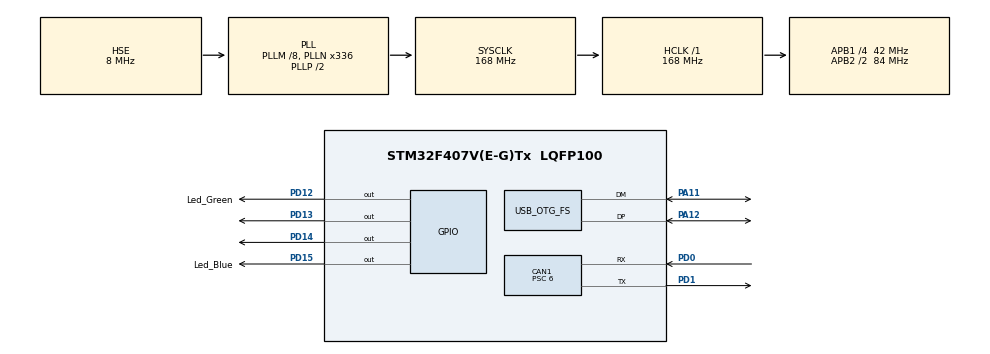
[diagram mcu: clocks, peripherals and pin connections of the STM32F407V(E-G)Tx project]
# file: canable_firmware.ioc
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CAN1.BS1=CAN_BS1_11TQ
CAN1.BS2=CAN_BS2_2TQ
CAN1.CalculateBaudRate=500000
CAN1.CalculateTimeBit=2000
CAN1.CalculateTimeQuantum=142.85714285714286
CAN1.Prescaler=6
Mcu.Family=STM32F4
Mcu.Name=STM32F407V(E-G)Tx
Mcu.Package=LQFP100
NVIC.CAN1_RX0_IRQn=true\:0\:2\:false\:false\:true\:true\:true\:true
NVIC.CAN1_RX1_IRQn=true\:0\:0\:false\:false\:true\:true\:true\:true
NVIC.CAN1_SCE_IRQn=true\:0\:0\:false\:false\:true\:true\:true\:true
NVIC.CAN1_TX_IRQn=true\:0\:0\:false\:false\:true\:true\:true\:true
NVIC.OTG_FS_IRQn=true\:0\:0\:false\:false\:true\:true\:true\:true
NVIC.PriorityGroup=NVIC_PRIORITYGROUP_0
PA11.Mode=Device_Only
PA11.Signal=USB_OTG_FS_DM
PA12.Mode=Device_Only
PA12.Signal=USB_OTG_FS_DP
PC14-OSC32_IN.Mode=LSE-External-Oscillator
PC14-OSC32_IN.Signal=RCC_OSC32_IN
PC15-OSC32_OUT.Mode=LSE-External-Oscillator
PC15-OSC32_OUT.Signal=RCC_OSC32_OUT
PD0.Mode=CAN_Activate
PD0.Signal=CAN1_RX
PD1.Mode=CAN_Activate
PD1.Signal=CAN1_TX
PD12.GPIO_Label=Led_Green
PD12.Signal=GPIO_Output
PD13.Signal=GPIO_Output
PD14.Signal=GPIO_Output
PD15.GPIO_Label=Led_Blue
PD15.Signal=GPIO_Output
PH0-OSC_IN.Mode=HSE-External-Oscillator
PH0-OSC_IN.Signal=RCC_OSC_IN
PH1-OSC_OUT.Mode=HSE-External-Oscillator
PH1-OSC_OUT.Signal=RCC_OSC_OUT
ProjectManager.HeapSize=0x200
ProjectManager.StackSize=0x400
ProjectManager.TargetToolchain=STM32CubeIDE
RCC.48MHZClocksFreq_Value=48000000
RCC.AHBFreq_Value=168000000
RCC.APB1CLKDivider=RCC_HCLK_DIV4
RCC.APB1Freq_Value=42000000
RCC.APB1TimFreq_Value=84000000
RCC.APB2CLKDivider=RCC_HCLK_DIV2
RCC.APB2Freq_Value=84000000
RCC.APB2TimFreq_Value=168000000
RCC.CortexFreq_Value=168000000
RCC.HCLKFreq_Value=168000000
RCC.HSE_VALUE=8000000
RCC.HSI_VALUE=16000000
RCC.PLLM=8
RCC.PLLN=336
RCC.PLLQ=7
RCC.SYSCLKFreq_VALUE=168000000
RCC.SYSCLKSource=RCC_SYSCLKSOURCE_PLLCLK
RCC.VCOOutputFreq_Value=336000000
USB_DEVICE.CLASS_NAME_FS=CUSTOM_HID
USB_DEVICE.USBD_CUSTOMHID_OUTREPORT_BUF_SIZE-CUSTOM_HID_FS=17
USB_DEVICE.USBD_CUSTOM_HID_REPORT_DESC_SIZE-CUSTOM_HID_FS=33
USB_DEVICE.VirtualMode-CUSTOM_HID_FS=CustomHid
USB_DEVICE.VirtualModeFS=Custom_Hid_FS
USB_OTG_FS.VirtualMode=Device_Only
VP_USB_DEVICE_VS_USB_DEVICE_CUSTOM_HID_FS.Mode=CUSTOM_HID_FS
board=STM32F407G-DISC1

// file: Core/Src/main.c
/* USER CODE BEGIN Header */
/**
  ******************************************************************************
  * @file           : main.c
  * @brief          : Main program body
  ******************************************************************************
  * @attention
  *
  * Copyright (c) 2023 STMicroelectronics.
  * All rights reserved.
  *
  * This software is licensed under terms that can be found in the LICENSE file
  * in the root directory of this software component.
  * If no LICENSE file comes with this software, it is provided AS-IS.
  *
  ******************************************************************************
  */
/* USER CODE END Header */
#include "main.h"
#include "usb_device.h"

/* USER CODE BEGIN Includes */
#include "PollingRoutines.h"
#include "CAN_Filter.h"
/* USER CODE END Includes */

CAN_HandleTypeDef hcan1;

void SystemClock_Config(void);
static void MX_GPIO_Init(void);
static void MX_CAN1_Init(void);

/* USER CODE BEGIN 0 */
CAN_HandleTypeDef hcan1;
CAN_TxHeaderTypeDef pHeader; //declare a specific header for message transmittions
CAN_RxHeaderTypeDef pRxHeader; //declare header for message reception
uint32_t TxMailbox;
uint8_t a,r; //declare byte to be transmitted //declare a receive byte
CAN_FilterTypeDef sFilterConfig; //declare CAN filter structure

/* USER CODE END 0 */

int main(void)
{

  /* MCU Configuration--------------------------------------------------------*/

  /* Reset of all peripherals, Initializes the Flash interface and the Systick. */
  HAL_Init();

  /* Configure the system clock */
  SystemClock_Config();

  /* Initialize all configured peripherals */
  MX_GPIO_Init();
  MX_CAN1_Init();
  MX_USB_DEVICE_Init();
  /* USER CODE BEGIN 2 */
  SetCanFilter();
  /* USER CODE END 2 */

  /* Infinite loop */
  while (1)
  {

    /* USER CODE BEGIN 3 */
	  PollingRoutine();
	/* USER CODE END 3 */
  }

}

void SystemClock_Config(void)
{
  RCC_OscInitTypeDef RCC_OscInitStruct = {0};
  RCC_ClkInitTypeDef RCC_ClkInitStruct = {0};

  /** Configure the main internal regulator output voltage
  */
  __HAL_RCC_PWR_CLK_ENABLE();
  __HAL_PWR_VOLTAGESCALING_CONFIG(PWR_REGULATOR_VOLTAGE_SCALE1);

  /** Initializes the RCC Oscillators according to the specified parameters
  * in the RCC_OscInitTypeDef structure.
  */
  RCC_OscInitStruct.OscillatorType = RCC_OSCILLATORTYPE_HSE;
  RCC_OscInitStruct.HSEState = RCC_HSE_ON;
  RCC_OscInitStruct.PLL.PLLState = RCC_PLL_ON;
  RCC_OscInitStruct.PLL.PLLSource = RCC_PLLSOURCE_HSE;
  RCC_OscInitStruct.PLL.PLLM = 8;
  RCC_OscInitStruct.PLL.PLLN = 336;
  RCC_OscInitStruct.PLL.PLLP = RCC_PLLP_DIV2;
  RCC_OscInitStruct.PLL.PLLQ = 7;
  if (HAL_RCC_OscConfig(&RCC_OscInitStruct) != HAL_OK)
  {
    Error_Handler();
  }

  /** Initializes the CPU, AHB and APB buses clocks
  */
  RCC_ClkInitStruct.ClockType = RCC_CLOCKTYPE_HCLK|RCC_CLOCKTYPE_SYSCLK
                              |RCC_CLOCKTYPE_PCLK1|RCC_CLOCKTYPE_PCLK2;
  RCC_ClkInitStruct.SYSCLKSource = RCC_SYSCLKSOURCE_PLLCLK;
  RCC_ClkInitStruct.AHBCLKDivider = RCC_SYSCLK_DIV1;
  RCC_ClkInitStruct.APB1CLKDivider = RCC_HCLK_DIV4;
  RCC_ClkInitStruct.APB2CLKDivider = RCC_HCLK_DIV2;

  if (HAL_RCC_ClockConfig(&RCC_ClkInitStruct, FLASH_LATENCY_5) != HAL_OK)
  {
    Error_Handler();
  }
}

static void MX_CAN1_Init(void)
{

  hcan1.Instance = CAN1;
  hcan1.Init.Prescaler = 6;
  hcan1.Init.Mode = CAN_MODE_NORMAL;
  hcan1.Init.SyncJumpWidth = CAN_SJW_1TQ;
  hcan1.Init.TimeSeg1 = CAN_BS1_11TQ;
  hcan1.Init.TimeSeg2 = CAN_BS2_2TQ;
  hcan1.Init.TimeTriggeredMode = DISABLE;
  hcan1.Init.AutoBusOff = DISABLE;
  hcan1.Init.AutoWakeUp = DISABLE;
  hcan1.Init.AutoRetransmission = DISABLE;
  hcan1.Init.ReceiveFifoLocked = DISABLE;
  hcan1.Init.TransmitFifoPriority = DISABLE;
  if (HAL_CAN_Init(&hcan1) != HAL_OK)
  {
    Error_Handler();
  }

}

static void MX_GPIO_Init(void)
{
  GPIO_InitTypeDef GPIO_InitStruct = {0};

  /* GPIO Ports Clock Enable */
  __HAL_RCC_GPIOC_CLK_ENABLE();
  __HAL_RCC_GPIOH_CLK_ENABLE();
  __HAL_RCC_GPIOD_CLK_ENABLE();
  __HAL_RCC_GPIOA_CLK_ENABLE();

  /*Configure GPIO pin Output Level */
  HAL_GPIO_WritePin(GPIOD, Led_Green_Pin|GPIO_PIN_13|GPIO_PIN_14|Led_Blue_Pin, GPIO_PIN_RESET);

  /*Configure GPIO pins : Led_Green_Pin PD13 PD14 Led_Blue_Pin */
  GPIO_InitStruct.Pin = Led_Green_Pin|GPIO_PIN_13|GPIO_PIN_14|Led_Blue_Pin;
  GPIO_InitStruct.Mode = GPIO_MODE_OUTPUT_PP;
  GPIO_InitStruct.Pull = GPIO_NOPULL;
  GPIO_InitStruct.Speed = GPIO_SPEED_FREQ_LOW;
  HAL_GPIO_Init(GPIOD, &GPIO_InitStruct);

}

void Error_Handler(void)
{
  __disable_irq();
  while (1)
  {
  }
}
